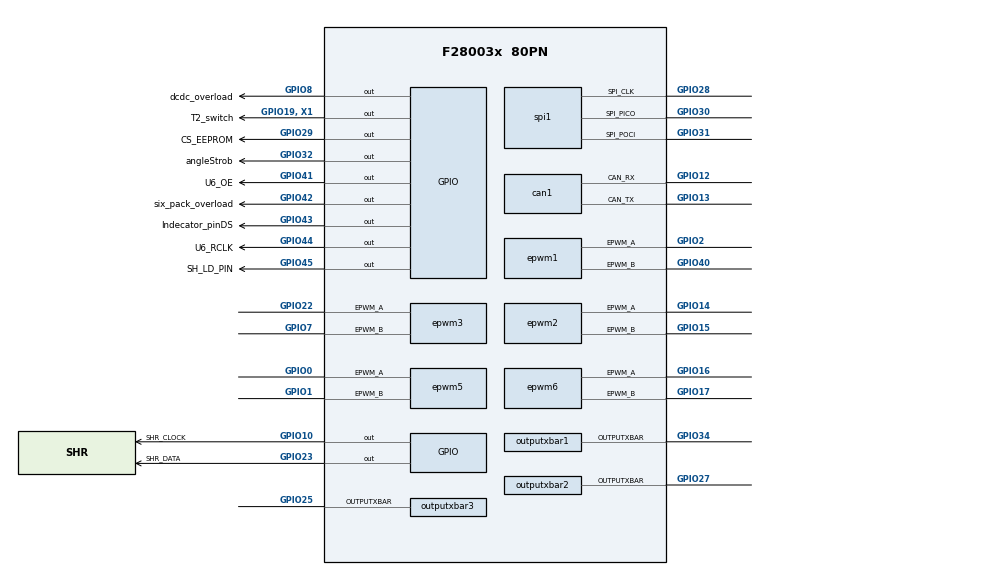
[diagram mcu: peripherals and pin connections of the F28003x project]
/**
 * @cliArgs --device "F28003x" --part "F28003x_80PN" --package "80PN" --context "system" --product "C2000WARE@6.00.01.00"
 * @versions {"tool":"1.27.0+4565"}
 */

/**
 * Import the modules used in this configuration.
 */
const adc              = scripting.addModule("/driverlib/adc.js", {}, false);
const adc1             = adc.addInstance();
const adc2             = adc.addInstance();
const adc3             = adc.addInstance();
const analog           = scripting.addModule("/driverlib/analog.js", {}, false);
const analog1          = analog.addInstance();
const asysctl          = scripting.addModule("/driverlib/asysctl.js");
const can              = scripting.addModule("/driverlib/can.js", {}, false);
const can1             = can.addInstance();
const cla              = scripting.addModule("/driverlib/cla.js", {}, false);
const cla1             = cla.addInstance();
const cmpss            = scripting.addModule("/driverlib/cmpss.js", {}, false);
const cmpss1           = cmpss.addInstance();
const cmpss2           = cmpss.addInstance();
const cmpss3           = cmpss.addInstance();
const cputimer         = scripting.addModule("/driverlib/cputimer.js", {}, false);
const cputimer1        = cputimer.addInstance();
const cputimer2        = cputimer.addInstance();
const device_support   = scripting.addModule("/driverlib/device_support.js");
const dma              = scripting.addModule("/driverlib/dma.js", {}, false);
const dma1             = dma.addInstance();
const epwm             = scripting.addModule("/driverlib/epwm.js");
const epwm1            = epwm.addInstance();
const epwm2            = epwm.addInstance();
const epwm3            = epwm.addInstance();
const epwm4            = epwm.addInstance();
const epwm5            = epwm.addInstance();
const epwm6            = epwm.addInstance();
const epwmxbar         = scripting.addModule("/driverlib/epwmxbar.js", {}, false);
const epwmxbar1        = epwmxbar.addInstance();
const epwmxbar2        = epwmxbar.addInstance();
const gpio             = scripting.addModule("/driverlib/gpio.js", {}, false);
const gpio1            = gpio.addInstance();
const gpio2            = gpio.addInstance();
const gpio3            = gpio.addInstance();
const gpio4            = gpio.addInstance();
const gpio5            = gpio.addInstance();
const gpio6            = gpio.addInstance();
const gpio7            = gpio.addInstance();
const gpio8            = gpio.addInstance();
const gpio9            = gpio.addInstance();
const gpio10           = gpio.addInstance();
const gpio11           = gpio.addInstance();
const inputxbar_input  = scripting.addModule("/driverlib/inputxbar_input.js", {}, false);
const inputxbar_input1 = inputxbar_input.addInstance();
const inputxbar_input2 = inputxbar_input.addInstance();
const memcfg           = scripting.addModule("/driverlib/memcfg.js");
const outputxbar       = scripting.addModule("/driverlib/outputxbar.js", {}, false);
const outputxbar1      = outputxbar.addInstance();
const outputxbar2      = outputxbar.addInstance();
const outputxbar3      = outputxbar.addInstance();
const outputxbar4      = outputxbar.addInstance();
const spi              = scripting.addModule("/driverlib/spi.js", {}, false);
const spi1             = spi.addInstance();
const sync             = scripting.addModule("/driverlib/sync.js");
const sysctl           = scripting.addModule("/driverlib/sysctl.js");

/**
 * Write custom configuration values to the imported modules.
 */
adc1.soc0UseSampleTimeCalculator    = true;
adc1.interruptPulseMode             = "ADC_PULSE_END_OF_CONV";
adc1.$name                          = "myADCA";
adc1.adcClockPrescaler              = "ADC_CLK_DIV_2_0";
adc1.ppb2SOCNumber                  = "ADC_SOC_NUMBER1";
adc1.ppb2HighTripLimit              = 4000;
adc1.ppb1HighTripLimit              = 2000;
adc1.ppb1LowTripLimit               = -2000;
adc1.enableInterrupt1               = true;
adc1.soc1SampleWindow               = 12;
adc1.soc0SampleWindow               = 12;
adc1.ppb2ReferenceOffset            = 2048;
adc1.socHighPriorityMode            = "ADC_PRI_ALL_HIPRI";
adc1.soc0Trigger                    = "ADC_TRIGGER_EPWM1_SOCA";
adc1.soc1Trigger                    = "ADC_TRIGGER_EPWM1_SOCA";
adc1.soc2Trigger                    = "ADC_TRIGGER_EPWM1_SOCA";
adc1.interrupt1SOCSource            = "ADC_SOC_NUMBER2";
adc1.enabledPPBs                    = ["ADC_PPB_NUMBER1","ADC_PPB_NUMBER2","ADC_PPB_NUMBER3"];
adc1.ppb3SOCNumber                  = "ADC_SOC_NUMBER2";
adc1.ppb3ReferenceOffset            = 2048;
adc1.soc2SampleWindow               = 12;
adc1.soc0Name                       = "SOC0_Udc";
adc1.soc0Channel                    = "ADC_CH_ADCIN15";
adc1.soc1Name                       = "SOC1_Vin";
adc1.soc1Channel                    = "ADC_CH_ADCIN4";
adc1.soc2Name                       = "SOC2_Idc";
adc1.soc2Channel                    = "ADC_CH_ADCIN12";
adc1.ppb1ReferenceOffset            = 200;
adc1.enableInterrupt1ContinuousMode = true;
adc1.soc3Channel                    = "ADC_CH_ADCIN10";
adc1.soc3Trigger                    = "ADC_TRIGGER_EPWM2_SOCA";
adc1.soc3SampleWindow               = 12;
adc1.interrupt2SOCSource            = "ADC_SOC_NUMBER3";
adc1.registerInterrupts             = ["1"];
adc1.enabledSOCs                    = ["ADC_SOC_NUMBER0","ADC_SOC_NUMBER1","ADC_SOC_NUMBER2"];
adc1.enabledInts                    = ["ADC_INT_NUMBER1"];
adc1.adcInt1.interruptHandler       = "Cla1Task1";

adc2.$name                          = "myADCB";
adc2.adcBase                        = "ADCB_BASE";
adc2.adcClockPrescaler              = "ADC_CLK_DIV_2_0";
adc2.interruptPulseMode             = "ADC_PULSE_END_OF_CONV";
adc2.enableInterrupt2               = true;
adc2.soc0Trigger                    = "ADC_TRIGGER_EPWM2_SOCA";
adc2.socHighPriorityMode            = "ADC_PRI_ALL_HIPRI";
adc2.enabledInts                    = ["ADC_INT_NUMBER1"];
adc2.ppb2SOCNumber                  = "ADC_SOC_NUMBER1";
adc2.soc2Channel                    = "ADC_CH_ADCIN9";
adc2.enableInterrupt1               = true;
adc2.ppb3SOCNumber                  = "ADC_SOC_NUMBER2";
adc2.ppb2ReferenceOffset            = 2048;
adc2.ppb1ReferenceOffset            = 2048;
adc2.soc1Trigger                    = "ADC_TRIGGER_EPWM2_SOCA";
adc2.soc2Trigger                    = "ADC_TRIGGER_EPWM2_SOCA";
adc2.soc2Name                       = "SOC2_Udc";
adc2.soc2SampleWindow               = 120;
adc2.soc0Name                       = "SOC0_Ia";
adc2.soc1Name                       = "SOC1_Ib";
adc2.enabledSOCs                    = ["ADC_SOC_NUMBER0","ADC_SOC_NUMBER1"];
adc2.interrupt1SOCSource            = "ADC_SOC_NUMBER1";
adc2.enabledPPBs                    = ["ADC_PPB_NUMBER1","ADC_PPB_NUMBER2"];
adc2.enableInterrupt1ContinuousMode = true;
adc2.soc0SampleWindow               = 120;
adc2.soc0Channel                    = "ADC_CH_ADCIN1";
adc2.soc1Channel                    = "ADC_CH_ADCIN7";
adc2.soc1SampleWindow               = 12;

adc3.$name                          = "myADCC";
adc3.adcBase                        = "ADCC_BASE";
adc3.adcClockPrescaler              = "ADC_CLK_DIV_2_0";
adc3.enabledSOCs                    = ["ADC_SOC_NUMBER0"];
adc3.soc0Channel                    = "ADC_CH_ADCIN12";
adc3.soc0Trigger                    = "ADC_TRIGGER_EPWM2_SOCA";
adc3.soc0SampleWindow               = 512;
adc3.interruptPulseMode             = "ADC_PULSE_END_OF_CONV";
adc3.enabledInts                    = ["ADC_INT_NUMBER1"];
adc3.enableInterrupt1               = true;
adc3.enableInterrupt1ContinuousMode = true;
adc3.registerInterrupts             = ["1"];
adc3.adcInt1.enableInterrupt        = true;

asysctl.enableTemperatureSensor = true;
asysctl.analogReference         = "INTERNAL";
asysctl.analogReferenceVoltage  = "1P65";

can1.AutoBusOnTimer        = 10;
can1.bitRate               = "1000000";
can1.msgObjsUsed           = [1,2,3,4,5,6,7,8,9,10,11,12,13,32];
can1.$name                 = "myDCAN";
can1.can.$assign           = "CANA";
can1.can.can_rxPin.$assign = "GPIO12";
can1.can.can_txPin.$assign = "GPIO13";
can1.rxQual.padConfig      = "STD";
can1.txQual.padConfig      = "STD";
can1.msgObj1.$name         = "msgObj2";
can1.msgObj1.msgLen        = 8;
can1.msgObj1.msgID         = 2;
can1.msgObj2.$name         = "msgObj3";
can1.msgObj2.msgType       = "CAN_MSG_OBJ_TYPE_TX";
can1.msgObj2.msgLen        = 8;
can1.msgObj2.msgID         = 1;
can1.msgObj3.$name         = "msgObj4";
can1.msgObj3.msgType       = "CAN_MSG_OBJ_TYPE_TX";
can1.msgObj3.msgLen        = 8;
can1.msgObj3.msgID         = 103;
can1.msgObj4.$name         = "msgObj0";
can1.msgObj4.msgType       = "CAN_MSG_OBJ_TYPE_TX";
can1.msgObj4.msgLen        = 8;
can1.msgObj4.msgID         = 104;
can1.msgObj5.$name         = "msgObj5";
can1.msgObj5.msgType       = "CAN_MSG_OBJ_TYPE_TX";
can1.msgObj5.msgLen        = 8;
can1.msgObj5.msgID         = 110;
can1.msgObj6.$name         = "msgObj6";
can1.msgObj6.msgID         = 100;
can1.msgObj6.msgType       = "CAN_MSG_OBJ_TYPE_TX";
can1.msgObj6.msgLen        = 8;
can1.msgObj7.$name         = "msgObj7";
can1.msgObj7.msgID         = 101;
can1.msgObj7.msgType       = "CAN_MSG_OBJ_TYPE_TX";
can1.msgObj7.msgLen        = 8;
can1.msgObj8.$name         = "msgObj8";
can1.msgObj8.msgID         = 102;
can1.msgObj8.msgType       = "CAN_MSG_OBJ_TYPE_TX";
can1.msgObj8.msgLen        = 8;
can1.msgObj9.$name         = "msgObj9";
can1.msgObj9.msgID         = 107;
can1.msgObj9.msgType       = "CAN_MSG_OBJ_TYPE_TX";
can1.msgObj9.msgLen        = 8;
can1.msgObj10.$name        = "msgObj10";
can1.msgObj10.msgID        = 106;
can1.msgObj10.msgType      = "CAN_MSG_OBJ_TYPE_TX";
can1.msgObj10.msgLen       = 8;
can1.msgObj11.$name        = "msgObj11";
can1.msgObj11.msgID        = 109;
can1.msgObj11.msgType      = "CAN_MSG_OBJ_TYPE_TX";
can1.msgObj11.msgLen       = 8;
can1.msgObj12.$name        = "msgObj12";
can1.msgObj12.msgType      = "CAN_MSG_OBJ_TYPE_TX";
can1.msgObj12.msgLen       = 8;
can1.msgObj12.msgID        = 118;
can1.msgObj13.$name        = "msgObj13";
can1.msgObj13.msgID        = 116;
can1.msgObj13.msgType      = "CAN_MSG_OBJ_TYPE_TX";
can1.msgObj13.msgLen       = 8;
can1.msgObj32.$name        = "msgObj1";
can1.msgObj32.msgType      = "CAN_MSG_OBJ_TYPE_TX";
can1.msgObj32.msgLen       = 8;
can1.msgObj32.msgID        = 131;

cla1.enable_CLA_TASK_2  = false;
cla1.enable_CLA_TASK_3  = false;
cla1.enable_CLA_TASK_4  = false;
cla1.enable_CLA_TASK_5  = false;
cla1.enable_CLA_TASK_6  = false;
cla1.enable_CLA_TASK_8  = false;
cla1.cpuint_CLA_TASK_2  = false;
cla1.cpuint_CLA_TASK_3  = false;
cla1.cpuint_CLA_TASK_4  = false;
cla1.cpuint_CLA_TASK_5  = false;
cla1.cpuint_CLA_TASK_6  = false;
cla1.cpuint_CLA_TASK_8  = false;
cla1.$name              = "myCLA";
cla1.cpuint_CLA_TASK_1  = false;
cla1.trigger_CLA_TASK_1 = "CLA_TRIGGER_ADCA1";
cla1.trigger_CLA_TASK_7 = "CLA_TRIGGER_ADCB1";

const divider2       = system.clockTree["LOSPCP"];
divider2.divideValue = 1;

const divider3       = system.clockTree["MCANACLKDIV"];
divider3.divideValue = 3;

cmpss1.initFilterHigh      = true;
cmpss1.initFilterLow       = true;
cmpss1.dacValHigh          = 3700;
cmpss1.dacValLow           = 400;
cmpss1.dacValLoad          = "CMPSS_DACVAL_PWMSYNC";
cmpss1.$name               = "IphV";
cmpss1.highCTRIPOUT        = "CMPSS_TRIPOUT_FILTER";
cmpss1.highCTRIP           = "CMPSS_TRIP_FILTER";
cmpss1.samplePrescaleHigh  = 8;
cmpss1.sampleWindowHigh    = 32;
cmpss1.thresholdHigh       = 32;
cmpss1.samplePrescaleLow   = 8;
cmpss1.sampleWindowLow     = 32;
cmpss1.thresholdLow        = 32;
cmpss1.lowCTRIPOUT         = "CMPSS_TRIPOUT_FILTER";
cmpss1.lowCTRIP            = "CMPSS_TRIP_FILTER";
cmpss1.configBlanking      = "2";
cmpss1.pwmSyncSrc          = "2";
cmpss1.asysCMPHPMXSELValue = "4";
cmpss1.asysCMPLPMXSELValue = "4";
cmpss1.lowCompInvert       = true;
cmpss1.enableModule        = true;

cmpss2.enableModule        = true;
cmpss2.dacValLoad          = "CMPSS_DACVAL_PWMSYNC";
cmpss2.hysteresisVal       = "4";
cmpss2.lowCompInvert       = true;
cmpss2.initFilterHigh      = true;
cmpss2.initFilterLow       = true;
cmpss2.lowCTRIPOUT         = "CMPSS_TRIPOUT_FILTER";
cmpss2.highCTRIPOUT        = "CMPSS_TRIPOUT_FILTER";
cmpss2.sampleWindowLow     = 31;
cmpss2.sampleWindowHigh    = 31;
cmpss2.configBlanking      = "2";
cmpss2.highCTRIP           = "CMPSS_TRIP_FILTER";
cmpss2.lowCTRIP            = "CMPSS_TRIP_FILTER";
cmpss2.dacValHigh          = 3700;
cmpss2.thresholdHigh       = 30;
cmpss2.dacValLow           = 400;
cmpss2.clearFilterLatchLow = true;
cmpss2.latchResetLow       = true;
cmpss2.thresholdLow        = 30;
cmpss2.configLatchLow      = true;
cmpss2.samplePrescaleHigh  = 16;
cmpss2.samplePrescaleLow   = 16;
cmpss2.cmpssBase           = "CMPSS2_BASE";
cmpss2.$name               = "Idc";

cmpss3.initFilterLow       = true;
cmpss3.sampleWindowLow     = 31;
cmpss3.highCTRIP           = "CMPSS_TRIP_FILTER";
cmpss3.lowCTRIP            = "CMPSS_TRIP_FILTER";
cmpss3.cmpssBase           = "CMPSS3_BASE";
cmpss3.asysCMPLPMXSELValue = "2";
cmpss3.lowCTRIPOUT         = "CMPSS_TRIPOUT_FILTER";
cmpss3.thresholdLow        = 31;
cmpss3.highCTRIPOUT        = "CMPSS_TRIPOUT_FILTER";
cmpss3.initFilterHigh      = true;
cmpss3.sampleWindowHigh    = 32;
cmpss3.thresholdHigh       = 32;
cmpss3.samplePrescaleHigh  = 8;
cmpss3.$name               = "IphU";
cmpss3.configBlanking      = "2";
cmpss3.lowCompInvert       = true;
cmpss3.samplePrescaleLow   = 8;
cmpss3.dacValHigh          = 4000;
cmpss3.dacValLow           = 1000;
cmpss3.pwmSyncSrc          = "2";
cmpss3.asysCMPHPMXSELValue = "2";
cmpss3.enableModule        = true;

analog1.$name            = "myANALOGPinMux0";
adc1.analog              = analog1;
adc2.analog              = analog1;
cmpss1.analog            = analog1;
cmpss2.analog            = analog1;
cmpss3.analog            = analog1;
analog1.useCase          = "CUSTOM";
analog1.useInterfacePins = ["A0/B15/C15/DACA_OUT","A1/B7/DACB_OUT","A10/B1/C10","A11/B10/C0","A12, C1","A15, C7/B9","A4/B8, C14"];
adc3.analog              = analog1;

cputimer1.$name          = "myCPUTIMER0";
cputimer1.timerPeriod    = 2400000;
cputimer1.emulationMode  = "CPUTIMER_EMULATIONMODE_RUNFREE";
cputimer1.timerPrescaler = 1;

cputimer2.$name          = "myCPUTIMER1";
cputimer2.cputimerBase   = "CPUTIMER1_BASE";
cputimer2.emulationMode  = "CPUTIMER_EMULATIONMODE_RUNFREE";
cputimer2.timerPeriod    = 2400000;
cputimer2.timerPrescaler = 1;

dma1.enableTriggers         = true;
dma1.triggerSource          = "DMA_TRIGGER_CANAIF3";
dma1.useInterrupts          = true;
dma1.registerInterrupts     = true;
dma1.enableInterrupts       = true;
dma1.interruptMode          = "DMA_INT_AT_END";
dma1.continuousModeConfig   = "DMA_CFG_CONTINUOUS_ENABLE";
dma1.startChannel           = true;
dma1.srcBurstStep           = 1;
dma1.destBurstStep          = 1;
dma1.destWrapSize           = 100;
dma1.emulationMode          = "DMA_EMULATION_FREE_RUN";
dma1.databusWidthConfig     = "DMA_CFG_SIZE_32BIT";
dma1.burstSize              = 2;
dma1.oneShotConfig          = "DMA_CFG_ONESHOT_ENABLE";
dma1.dmaBase                = "DMA_CH6_BASE";
dma1.$name                  = "DMA6";
dma1.dmaInt.enableInterrupt = true;

epwm.commentOutDefaultCode = true;
epwm.generateInitFunctions = true;

epwm1.epwmTimebase_emulationMode                                          = "EPWM_EMULATION_FREE_RUN";
epwm1.epwmTimebase_hsClockDiv                                             = "EPWM_HSCLOCK_DIVIDER_1";
epwm1.epwmTimebase_counterMode                                            = "EPWM_COUNTER_MODE_UP_DOWN";
epwm1.epwmCounterCompare_cmpB                                             = 1;
epwm1.epwmCounterCompare_enableShadowLoadModeCMPB                         = false;
epwm1.epwmActionQualifier_EPWM_AQ_OUTPUT_A_shadowMode                     = true;
epwm1.epwmDeadband_enableRED                                              = true;
epwm1.epwmDeadband_enableFED                                              = true;
epwm1.epwmDeadband_dbControlGld                                           = true;
epwm1.epwmDeadband_redGld                                                 = true;
epwm1.epwmDeadband_fedGld                                                 = true;
epwm1.epwmTimebase_counterModeAfterSync                                   = "EPWM_COUNT_MODE_UP_AFTER_SYNC";
epwm1.epwmActionQualifier_EPWM_AQ_OUTPUT_B_shadowMode                     = true;
epwm1.epwmDigitalCompare_EPWM_TZ_DC_OUTPUT_A1                             = "EPWM_TZ_EVENT_DCXH_HIGH";
epwm1.epwmTimebase_periodGld                                              = true;
epwm1.epwmDigitalCompare_EPWM_DC_TYPE_DCAH                                = "EPWM_DC_TRIP_TRIPIN4";
epwm1.epwmTimebase_period                                                 = 60000;
epwm1.copyFrom                                                            = "myEPWM4";
epwm1.epwmTimebase_syncInPulseSource                                      = "EPWM_SYNC_IN_PULSE_SRC_DISABLE";
epwm1.epwmTimebase_syncOutPulseMode                                       = ["EPWM_SYNC_OUT_PULSE_ON_CNTR_ZERO"];
epwm1.epwmActionQualifier_t1Source                                        = "EPWM_AQ_TRIGGER_EVENT_TRIG_TZ_1";
epwm1.epwmActionQualifier_t2Source                                        = "EPWM_AQ_TRIGGER_EVENT_TRIG_TZ_1";
epwm1.epwmTripZone_registerInterrupts                                     = true;
epwm1.epwmDigitalCompare_EPWM_DC_MODULE_A_EPWM_DC_EVENT_1_latchClearEvent = "EPWM_DC_CBC_LATCH_CLR_ON_CNTR_PERIOD";
epwm1.epwmDigitalCompare_EPWM_DC_MODULE_A_EPWM_DC_EVENT_2_eventSync       = "EPWM_DC_EVENT_INPUT_NOT_SYNCED";
epwm1.epwmEventTrigger_EPWM_SOC_A_triggerEnable                           = true;
epwm1.epwmEventTrigger_EPWM_SOC_A_triggerEventPrescalar                   = "1";
epwm1.epwmDigitalCompare_EPWM_DC_TYPE_DCBH                                = "EPWM_DC_TRIP_TRIPIN4";
epwm1.epwmDigitalCompare_EPWM_TZ_DC_OUTPUT_B1                             = "EPWM_TZ_EVENT_DCXH_HIGH";
epwm1.epwmTripZone_tzInterruptSource                                      = ["EPWM_TZ_INTERRUPT_OST"];
epwm1.epwmTripZone_oneShotSource                                          = ["EPWM_TZ_SIGNAL_DCAEVT1","EPWM_TZ_SIGNAL_DCBEVT1"];
epwm1.epwmTripZone_EPWM_TZ_ACTION_EVENT_DCAEVT1                           = "EPWM_TZ_ACTION_DISABLE";
epwm1.epwmTripZone_EPWM_TZ_ACTION_EVENT_DCAEVT2                           = "EPWM_TZ_ACTION_DISABLE";
epwm1.epwmTripZone_EPWM_TZ_ACTION_EVENT_DCBEVT1                           = "EPWM_TZ_ACTION_DISABLE";
epwm1.epwmTripZone_EPWM_TZ_ACTION_EVENT_DCBEVT2                           = "EPWM_TZ_ACTION_DISABLE";
epwm1.$name                                                               = "EPWM2_Iu";
epwm1.epwmActionQualifier_EPWM_AQ_OUTPUT_A_ON_TIMEBASE_UP_CMPA            = "EPWM_AQ_OUTPUT_LOW";
epwm1.epwmActionQualifier_EPWM_AQ_OUTPUT_A_ON_TIMEBASE_DOWN_CMPA          = "EPWM_AQ_OUTPUT_HIGH";
epwm1.epwmDeadband_polarityRED                                            = "EPWM_DB_POLARITY_ACTIVE_LOW";
epwm1.epwmDeadband_delayRED                                               = 120;
epwm1.epwmDeadband_delayFED                                               = 120;
epwm1.epwmTripZone_EPWM_TZ_ACTION_EVENT_TZA                               = "EPWM_TZ_ACTION_HIGH";
epwm1.epwmTripZone_EPWM_TZ_ACTION_EVENT_TZB                               = "EPWM_TZ_ACTION_HIGH";
epwm1.epwmCounterCompare_cmpA                                             = 1;
epwm1.epwmEventTrigger_EPWM_SOC_A_triggerSource                           = "EPWM_SOC_TBCTR_ZERO";
epwm1.epwm.$assign                                                        = "EPWM2";
epwm1.epwm.epwm_aPin.$assign                                              = "GPIO2";
epwm1.epwm.epwm_bPin.$assign                                              = "GPIO40";
epwm1.epwmTZInt.enableInterrupt                                           = true;

epwm2.epwmTimebase_emulationMode                                 = "EPWM_EMULATION_FREE_RUN";
epwm2.epwmTimebase_hsClockDiv                                    = "EPWM_HSCLOCK_DIVIDER_1";
epwm2.epwmTimebase_counterMode                                   = "EPWM_COUNTER_MODE_UP_DOWN";
epwm2.epwmCounterCompare_cmpB                                    = 1;
epwm2.epwmCounterCompare_enableShadowLoadModeCMPB                = false;
epwm2.epwmActionQualifier_EPWM_AQ_OUTPUT_A_shadowMode            = true;
epwm2.epwmDeadband_enableRED                                     = true;
epwm2.epwmDeadband_enableFED                                     = true;
epwm2.epwmDeadband_dbControlGld                                  = true;
epwm2.epwmDeadband_redGld                                        = true;
epwm2.epwmDeadband_fedGld                                        = true;
epwm2.epwmTimebase_phaseEnable                                   = true;
epwm2.epwmTimebase_counterModeAfterSync                          = "EPWM_COUNT_MODE_UP_AFTER_SYNC";
epwm2.epwmActionQualifier_EPWM_AQ_OUTPUT_B_shadowMode            = true;
epwm2.epwmTimebase_periodLoadEvent                               = "EPWM_SHADOW_LOAD_MODE_SYNC";
epwm2.epwmDigitalCompare_EPWM_TZ_DC_OUTPUT_A1                    = "EPWM_TZ_EVENT_DCXH_HIGH";
epwm2.epwmEventTrigger_EPWM_SOC_A_triggerEnable                  = true;
epwm2.epwmEventTrigger_EPWM_SOC_A_triggerSource                  = "EPWM_SOC_TBCTR_PERIOD";
epwm2.epwmEventTrigger_EPWM_SOC_A_triggerEventPrescalar          = "1";
epwm2.epwmTimebase_periodGld                                     = true;
epwm2.epwmTripZone_EPWM_TZ_ACTION_EVENT_DCAEVT1                  = "EPWM_TZ_ACTION_DISABLE";
epwm2.epwmTripZone_EPWM_TZ_ACTION_EVENT_DCAEVT2                  = "EPWM_TZ_ACTION_DISABLE";
epwm2.epwmTripZone_EPWM_TZ_ACTION_EVENT_DCBEVT1                  = "EPWM_TZ_ACTION_DISABLE";
epwm2.epwmTripZone_EPWM_TZ_ACTION_EVENT_DCBEVT2                  = "EPWM_TZ_ACTION_DISABLE";
epwm2.epwmDigitalCompare_EPWM_DC_TYPE_DCAH                       = "EPWM_DC_TRIP_TRIPIN4";
epwm2.epwmTimebase_period                                        = 60000;
epwm2.epwmCounterCompare_cmpA                                    = 30000;
epwm2.copyFrom                                                   = "myEPWM4";
epwm2.epwmTimebase_periodLink                                    = "EPWM_LINK_WITH_EPWM_2";
epwm2.epwmTimebase_syncInPulseSource                             = "EPWM_SYNC_IN_PULSE_SRC_SYNCOUT_EPWM2";
epwm2.$name                                                      = "EPWM3_Iw";
epwm2.epwmTripZone_oneShotSource                                 = ["EPWM_TZ_SIGNAL_DCAEVT1","EPWM_TZ_SIGNAL_DCBEVT1"];
epwm2.epwmActionQualifier_EPWM_AQ_OUTPUT_A_ON_TIMEBASE_UP_CMPA   = "EPWM_AQ_OUTPUT_LOW";
epwm2.epwmActionQualifier_EPWM_AQ_OUTPUT_A_ON_TIMEBASE_DOWN_CMPA = "EPWM_AQ_OUTPUT_HIGH";
epwm2.epwmDeadband_polarityRED                                   = "EPWM_DB_POLARITY_ACTIVE_LOW";
epwm2.epwmDeadband_delayRED                                      = 120;
epwm2.epwmDeadband_delayFED                                      = 120;
epwm2.epwmTripZone_EPWM_TZ_ACTION_EVENT_TZA                      = "EPWM_TZ_ACTION_HIGH";
epwm2.epwmTripZone_EPWM_TZ_ACTION_EVENT_TZB                      = "EPWM_TZ_ACTION_HIGH";
epwm2.epwm.$assign                                               = "EPWM3";
epwm2.epwm.epwm_aPin.$assign                                     = "GPIO14";
epwm2.epwm.epwm_bPin.$assign                                     = "GPIO15";

epwm3.copyFrom                                                            = "myEPWM1";
epwm3.epwmTimebase_emulationMode                                          = "EPWM_EMULATION_FREE_RUN";
epwm3.epwmTimebase_hsClockDiv                                             = "EPWM_HSCLOCK_DIVIDER_1";
epwm3.epwmTimebase_period                                                 = 60000;
epwm3.epwmTimebase_periodGld                                              = true;
epwm3.epwmTimebase_counterMode                                            = "EPWM_COUNTER_MODE_UP_DOWN";
epwm3.epwmTimebase_counterModeAfterSync                                   = "EPWM_COUNT_MODE_UP_AFTER_SYNC";
epwm3.epwmTimebase_syncOutPulseMode                                       = ["EPWM_SYNC_OUT_PULSE_ON_CNTR_ZERO"];
epwm3.epwmCounterCompare_cmpA                                             = 30000;
epwm3.epwmCounterCompare_cmpB                                             = 1;
epwm3.epwmCounterCompare_enableShadowLoadModeCMPB                         = false;
epwm3.epwmActionQualifier_t1Source                                        = "EPWM_AQ_TRIGGER_EVENT_TRIG_TZ_1";
epwm3.epwmActionQualifier_t2Source                                        = "EPWM_AQ_TRIGGER_EVENT_TRIG_TZ_1";
epwm3.epwmActionQualifier_EPWM_AQ_OUTPUT_A_shadowMode                     = true;
epwm3.epwmActionQualifier_EPWM_AQ_OUTPUT_B_shadowMode                     = true;
epwm3.epwmDeadband_enableRED                                              = true;
epwm3.epwmDeadband_enableFED                                              = true;
epwm3.epwmDeadband_dbControlGld                                           = true;
epwm3.epwmDeadband_redGld                                                 = true;
epwm3.epwmDeadband_fedGld                                                 = true;
epwm3.epwmTripZone_EPWM_TZ_ACTION_EVENT_TZA                               = "EPWM_TZ_ACTION_DISABLE";
epwm3.epwmTripZone_EPWM_TZ_ACTION_EVENT_TZB                               = "EPWM_TZ_ACTION_DISABLE";
epwm3.epwmTripZone_EPWM_TZ_ACTION_EVENT_DCAEVT1                           = "EPWM_TZ_ACTION_DISABLE";
epwm3.epwmTripZone_EPWM_TZ_ACTION_EVENT_DCAEVT2                           = "EPWM_TZ_ACTION_DISABLE";
epwm3.epwmTripZone_EPWM_TZ_ACTION_EVENT_DCBEVT1                           = "EPWM_TZ_ACTION_DISABLE";
epwm3.epwmTripZone_EPWM_TZ_ACTION_EVENT_DCBEVT2                           = "EPWM_TZ_ACTION_DISABLE";
epwm3.epwmTripZone_oneShotSource                                          = ["EPWM_TZ_SIGNAL_DCAEVT1"];
epwm3.epwmTripZone_tzInterruptSource                                      = ["EPWM_TZ_INTERRUPT_OST"];
epwm3.epwmDigitalCompare_EPWM_DC_TYPE_DCAH                                = "EPWM_DC_TRIP_TRIPIN4";
epwm3.epwmDigitalCompare_EPWM_TZ_DC_OUTPUT_A1                             = "EPWM_TZ_EVENT_DCXH_HIGH";
epwm3.epwmDigitalCompare_EPWM_DC_MODULE_A_EPWM_DC_EVENT_1_latchClearEvent = "EPWM_DC_CBC_LATCH_CLR_ON_CNTR_PERIOD";
epwm3.epwmDigitalCompare_EPWM_DC_MODULE_A_EPWM_DC_EVENT_2_eventSync       = "EPWM_DC_EVENT_INPUT_NOT_SYNCED";
epwm3.epwmEventTrigger_EPWM_SOC_A_triggerEnable                           = true;
epwm3.epwmEventTrigger_EPWM_SOC_A_triggerSource                           = "EPWM_SOC_TBCTR_PERIOD";
epwm3.epwmEventTrigger_EPWM_SOC_A_triggerEventPrescalar                   = "1";
epwm3.epwmTimebase_periodLink                                             = "EPWM_LINK_WITH_EPWM_2";
epwm3.epwmTimebase_phaseEnable                                            = true;
epwm3.epwmTimebase_syncInPulseSource                                      = "EPWM_SYNC_IN_PULSE_SRC_SYNCOUT_EPWM2";
epwm3.$name                                                               = "EPWM4_Iv";
epwm3.epwmActionQualifier_EPWM_AQ_OUTPUT_A_ON_TIMEBASE_UP_CMPA            = "EPWM_AQ_OUTPUT_LOW";
epwm3.epwmActionQualifier_EPWM_AQ_OUTPUT_A_ON_TIMEBASE_DOWN_CMPA          = "EPWM_AQ_OUTPUT_HIGH";
epwm3.epwmDeadband_polarityRED                                            = "EPWM_DB_POLARITY_ACTIVE_LOW";
epwm3.epwmDeadband_delayRED                                               = 120;
epwm3.epwmDeadband_delayFED                                               = 120;
epwm3.epwm.$assign                                                        = "EPWM4";
epwm3.epwm.epwm_aPin.$assign                                              = "GPIO22";
epwm3.epwm.epwm_bPin.$assign                                              = "GPIO7";

epwm4.$name                      = "myEPWM7";
epwm4.useCase                    = "CUSTOM";
epwm4.epwmTimebase_hsClockDiv    = "EPWM_HSCLOCK_DIVIDER_1";
epwm4.epwmTimebase_period        = 65535;
epwm4.epwmTimebase_counterMode   = "EPWM_COUNTER_MODE_UP";
epwm4.epwmTimebase_emulationMode = "EPWM_EMULATION_FREE_RUN";
epwm4.epwm.$assign               = "EPWM7";

epwm5.epwmTimebase_emulationMode                                          = "EPWM_EMULATION_FREE_RUN";
epwm5.epwmTimebase_hsClockDiv                                             = "EPWM_HSCLOCK_DIVIDER_1";
epwm5.epwmTimebase_counterMode                                            = "EPWM_COUNTER_MODE_UP_DOWN";
epwm5.epwmActionQualifier_EPWM_AQ_OUTPUT_A_ON_TIMEBASE_UP_CMPA            = "EPWM_AQ_OUTPUT_HIGH";
epwm5.epwmActionQualifier_EPWM_AQ_OUTPUT_A_ON_TIMEBASE_DOWN_CMPA          = "EPWM_AQ_OUTPUT_LOW";
epwm5.epwmTimebase_counterModeAfterSync                                   = "EPWM_COUNT_MODE_UP_AFTER_SYNC";
epwm5.epwmDigitalCompare_EPWM_TZ_DC_OUTPUT_A1                             = "EPWM_TZ_EVENT_DCXH_HIGH";
epwm5.epwmEventTrigger_EPWM_SOC_A_triggerEnable                           = true;
epwm5.epwmEventTrigger_EPWM_SOC_A_triggerSource                           = "EPWM_SOC_TBCTR_PERIOD";
epwm5.epwmEventTrigger_EPWM_SOC_A_triggerEventPrescalar                   = "1";
epwm5.epwmTripZone_EPWM_TZ_ACTION_EVENT_DCAEVT1                           = "EPWM_TZ_ACTION_DISABLE";
epwm5.epwmTripZone_EPWM_TZ_ACTION_EVENT_DCAEVT2                           = "EPWM_TZ_ACTION_DISABLE";
epwm5.epwmTripZone_EPWM_TZ_ACTION_EVENT_DCBEVT1                           = "EPWM_TZ_ACTION_DISABLE";
epwm5.epwmTripZone_EPWM_TZ_ACTION_EVENT_DCBEVT2                           = "EPWM_TZ_ACTION_DISABLE";
epwm5.epwmTripZone_oneShotSource                                          = ["EPWM_TZ_SIGNAL_DCAEVT1"];
epwm5.epwmDigitalCompare_EPWM_DC_TYPE_DCAH                                = "EPWM_DC_TRIP_TRIPIN4";
epwm5.epwmTripZone_EPWM_TZ_ACTION_EVENT_TZA                               = "EPWM_TZ_ACTION_DISABLE";
epwm5.copyFrom                                                            = "myEPWM4";
epwm5.epwmTimebase_syncInPulseSource                                      = "EPWM_SYNC_IN_PULSE_SRC_DISABLE";
epwm5.epwmTimebase_syncOutPulseMode                                       = ["EPWM_SYNC_OUT_PULSE_ON_CNTR_ZERO"];
epwm5.epwmActionQualifier_t1Source                                        = "EPWM_AQ_TRIGGER_EVENT_TRIG_TZ_1";
epwm5.epwmActionQualifier_t2Source                                        = "EPWM_AQ_TRIGGER_EVENT_TRIG_TZ_1";
epwm5.epwmTripZone_EPWM_TZ_ACTION_EVENT_TZB                               = "EPWM_TZ_ACTION_DISABLE";
epwm5.epwmTripZone_tzInterruptSource                                      = ["EPWM_TZ_INTERRUPT_OST"];
epwm5.epwmDigitalCompare_EPWM_DC_MODULE_A_EPWM_DC_EVENT_1_latchClearEvent = "EPWM_DC_CBC_LATCH_CLR_ON_CNTR_PERIOD";
epwm5.epwmDigitalCompare_EPWM_DC_MODULE_A_EPWM_DC_EVENT_2_eventSync       = "EPWM_DC_EVENT_INPUT_NOT_SYNCED";
epwm5.$name                                                               = "myEPWM1";
epwm5.epwmDeadband_enableRED                                              = true;
epwm5.epwmDeadband_enableFED                                              = true;
epwm5.epwmCounterCompare_enableShadowLoadModeCMPB                         = false;
epwm5.epwmActionQualifier_EPWM_AQ_OUTPUT_A_shadowMode                     = true;
epwm5.hrpwm_syncSource                                                    = "HRPWM_PWMSYNC_SOURCE_ZERO";
epwm5.epwmTimebase_period                                                 = 1200;
epwm5.epwmCounterCompare_cmpA                                             = 600;
epwm5.epwmDeadband_delayRED                                               = 100;
epwm5.epwmDeadband_delayFED                                               = 100;
epwm5.epwmCounterCompare_cmpB                                             = 1;
epwm5.epwmDeadband_polarityFED                                            = "EPWM_DB_POLARITY_ACTIVE_LOW";
epwm5.epwm.$assign                                                        = "EPWM1";
epwm5.epwm.epwm_aPin.$assign                                              = "GPIO0";
epwm5.epwm.epwm_bPin.$assign                                              = "GPIO1";

epwm6.$name                                                      = "myEPWM5";
epwm6.epwmTimebase_hsClockDiv                                    = "EPWM_HSCLOCK_DIVIDER_1";
epwm6.epwmTimebase_periodLink                                    = "EPWM_LINK_WITH_EPWM_1";
epwm6.epwmTimebase_periodGld                                     = true;
epwm6.epwmTimebase_counterMode                                   = "EPWM_COUNTER_MODE_UP_DOWN";
epwm6.epwmTimebase_counterModeAfterSync                          = "EPWM_COUNT_MODE_UP_AFTER_SYNC";
epwm6.epwmTimebase_phaseEnable                                   = true;
epwm6.epwmActionQualifier_EPWM_AQ_OUTPUT_A_ON_TIMEBASE_UP_CMPA   = "EPWM_AQ_OUTPUT_HIGH";
epwm6.epwmActionQualifier_EPWM_AQ_OUTPUT_A_ON_TIMEBASE_DOWN_CMPA = "EPWM_AQ_OUTPUT_LOW";
epwm6.epwmDeadband_enableRED                                     = true;
epwm6.epwmDeadband_enableFED                                     = true;
epwm6.epwmDeadband_redGld                                        = true;
epwm6.epwmDeadband_fedGld                                        = true;
epwm6.useCase                                                    = "CUSTOM";
epwm6.useInterfacePins                                           = ["EPWM#_A","EPWM#_B"];
epwm6.epwmTimebase_phaseShift                                    = 1200;
epwm6.epwmCounterCompare_enableShadowLoadModeCMPB                = false;
epwm6.epwmTimebase_emulationMode                                 = "EPWM_EMULATION_FREE_RUN";
epwm6.epwmTimebase_periodLoadEvent                               = "EPWM_SHADOW_LOAD_MODE_SYNC";
epwm6.epwmCounterCompare_cmpALink                                = "EPWM_LINK_WITH_EPWM_1";
epwm6.epwmCounterCompare_cmpAGld                                 = true;
epwm6.epwmActionQualifier_EPWM_AQ_OUTPUT_A_gld                   = true;
epwm6.epwmActionQualifier_EPWM_AQ_OUTPUT_A_shadowMode            = true;
epwm6.epwmActionQualifier_EPWM_AQ_OUTPUT_A_shadowEvent           = "EPWM_AQ_LOAD_ON_SYNC_ONLY";
epwm6.epwmDeadband_delayRED                                      = 100;
epwm6.epwmDeadband_delayFED                                      = 100;
epwm6.epwmTimebase_period                                        = 1200;
epwm6.epwmCounterCompare_cmpA                                    = 600;
epwm6.epwmDeadband_polarityFED                                   = "EPWM_DB_POLARITY_ACTIVE_LOW";
epwm6.epwm.$assign                                               = "EPWM5";
epwm6.epwm.epwm_aPin.$assign                                     = "GPIO16";
epwm6.epwm.epwm_bPin.$assign                                     = "GPIO17";

epwmxbar1.$name         = "myEPWMXBAR0";
epwmxbar1.mux0Config    = "XBAR_EPWM_MUX00_CMPSS1_CTRIPH_OR_L";
epwmxbar1.mux4Config    = "XBAR_EPWM_MUX04_CMPSS3_CTRIPH_OR_L";
epwmxbar1.mux6Config    = "XBAR_EPWM_MUX06_CMPSS4_CTRIPH_OR_L";
epwmxbar1.mux7Config    = "XBAR_EPWM_MUX07_INPUTXBAR4";
epwmxbar1.sourceSignals = ["CMPSS1_CTRIPH_OR_L","CMPSS3_CTRIPH_OR_L"];

epwmxbar2.$name           = "Idc_null";
epwmxbar2.tripInput       = "XBAR_TRIP5";
epwmxbar2.useSourceSelect = true;
epwmxbar2.sourceSignals   = ["CMPSS2_CTRIPH"];

gpio1.padConfig       = "PULLUP";
gpio1.$name           = "CS_EEPROM";
gpio1.direction       = "GPIO_DIR_MODE_OUT";
gpio1.gpioPin.$assign = "GPIO29";

gpio2.$name           = "T2_switch";
gpio2.direction       = "GPIO_DIR_MODE_OUT";
gpio2.gpioPin.$assign = "GPIO19, X1";

gpio3.$name           = "angleStrob";
gpio3.direction       = "GPIO_DIR_MODE_OUT";
gpio3.gpioPin.$assign = "GPIO32";

gpio4.writeInitialValue = true;
gpio4.initialValue      = 1;
gpio4.$name             = "six_pack_overload";
gpio4.qualMode          = "GPIO_QUAL_ASYNC";
gpio4.gpioPin.$assign   = "GPIO42";

gpio5.$name             = "SH_LD_PIN";
gpio5.direction         = "GPIO_DIR_MODE_OUT";
gpio5.writeInitialValue = true;
gpio5.initialValue      = 1;
gpio5.gpioPin.$assign   = "GPIO45";

gpio6.direction         = "GPIO_DIR_MODE_OUT";
gpio6.writeInitialValue = true;
gpio6.$name             = "SHR_CLOCK";
gpio6.gpioPin.$assign   = "GPIO10";

gpio7.$name           = "SHR_DATA";
gpio7.gpioPin.$assign = "GPIO23";

gpio8.direction       = "GPIO_DIR_MODE_OUT";
gpio8.$name           = "Indecator_pinDS";
gpio8.gpioPin.$assign = "GPIO43";

gpio9.$name           = "U6_OE";
gpio9.direction       = "GPIO_DIR_MODE_OUT";
gpio9.padConfig       = "OD";
gpio9.gpioPin.$assign = "GPIO41";

gpio10.$name           = "U6_RCLK";
gpio10.direction       = "GPIO_DIR_MODE_OUT";
gpio10.gpioPin.$assign = "GPIO44";

gpio11.qualMode          = "GPIO_QUAL_ASYNC";
gpio11.$name             = "dcdc_overload";
gpio11.writeInitialValue = true;
gpio11.initialValue      = 1;
gpio11.gpioPin.$assign   = "GPIO8";

inputxbar_input1.inputxbarInput = "XBAR_INPUT4";
inputxbar_input1.inputxbarGpio  = "GPIO42";
inputxbar_input1.$name          = "inv_overload";

inputxbar_input2.$name         = "dc_convertor_overload";
inputxbar_input2.inputxbarGpio = "GPIO8";

memcfg.config_MEMCFG_SECT_LS0 = "CLA_prog";
memcfg.config_MEMCFG_SECT_LS2 = "CLA_data";
memcfg.config_MEMCFG_SECT_LS1 = "CLA_data";
memcfg.access_MEMCFG_SECT_GS0 = ["MEMCFG_PROT_ALLOWCPUFETCH","MEMCFG_PROT_ALLOWCPUWRITE","MEMCFG_PROT_ALLOWDMAWRITE"];
memcfg.access_MEMCFG_SECT_GS1 = ["MEMCFG_PROT_ALLOWCPUFETCH","MEMCFG_PROT_ALLOWCPUWRITE","MEMCFG_PROT_ALLOWDMAWRITE"];
memcfg.access_MEMCFG_SECT_GS2 = ["MEMCFG_PROT_ALLOWCPUFETCH","MEMCFG_PROT_ALLOWCPUWRITE"];
memcfg.access_MEMCFG_SECT_GS3 = ["MEMCFG_PROT_ALLOWCPUFETCH","MEMCFG_PROT_ALLOWCPUWRITE"];

outputxbar1.$name                            = "myOUTPUTXBAR0";
outputxbar1.useSourceSelect                  = true;
outputxbar1.sourceSignals                    = ["CMPSS1_CTRIPOUTH_OR_L","CMPSS3_CTRIPOUTH_OR_L"];
outputxbar1.outputxbar.$assign               = "OUTPUTXBAR1";
outputxbar1.outputxbar.outputxbarPin.$assign = "GPIO34";

outputxbar2.useSourceSelect                  = true;
outputxbar2.sourceSignals                    = ["CMPSS1_CTRIPOUTH_OR_L"];
outputxbar2.$name                            = "cmp1HL";
outputxbar2.outputxbar.$assign               = "OUTPUTXBAR4";
outputxbar2.outputxbar.outputxbarPin.$assign = "GPIO27";

outputxbar3.$name                            = "myOUTPUTXBAR2";
outputxbar3.useSourceSelect                  = true;
outputxbar3.sourceSignals                    = ["CMPSS4_CTRIPOUTH_OR_L"];
outputxbar3.outputxbar.$assign               = "OUTPUTXBAR2";
outputxbar3.outputxbar.outputxbarPin.$assign = "GPIO25";

outputxbar4.useSourceSelect                                = true;
outputxbar4.sourceSignals                                  = ["CMPSS1_CTRIPOUTH_OR_L","CMPSS3_CTRIPOUTH_OR_L"];
outputxbar4.$name                                          = "cmp13HL";
outputxbar4.outputxbar.$assign                             = "OUTPUTXBAR3";
outputxbar4.outputxbar.outputxbarPin.$assignAllowConflicts = "GPIO26";

spi1.mode                    = "SPI_MODE_CONTROLLER";
spi1.$name                   = "mySPIB";
spi1.enabledInterrupts       = ["SPI_INT_RX_DATA_TX_EMPTY"];
spi1.txFifo                  = "SPI_FIFO_TX2";
spi1.rxFifo                  = "SPI_FIFO_RX2";
spi1.useInterfacePins        = ["SPI@_CLK","SPI@_SIMO","SPI@_SOMI"];
spi1.useInterrupts           = false;
spi1.useCase                 = "CUSTOM";
spi1.emulationMode           = "SPI_EMULATION_FREE_RUN";
spi1.bitRate                 = 30000000;
spi1.picoQual.$name          = "myGPIOQUAL0";
spi1.pociQual.$name          = "myGPIOQUAL3";
spi1.clkQual.$name           = "myGPIOQUAL2";
spi1.spi.$assign             = "SPIB";
spi1.spi.spi_picoPin.$assign = "GPIO30";
spi1.spi.spi_pociPin.$assign = "GPIO31";
spi1.spi.spi_clkPin.$assign  = "GPIO28";

sync.syncOutSource       = "SYSCTL_SYNC_OUT_SRC_EPWM2SYNCOUT";
sync.ADCSOCAOutputSelect = ["SYSCTL_ADCSOC_SRC_PWM2SOCA"];

sysctl.enable_SYSCTL_PERIPH_CLK_CPUBGCRC = false;
sysctl.enable_SYSCTL_PERIPH_CLK_HRCAL    = false;
sysctl.enable_SYSCTL_PERIPH_CLK_ERAD     = false;
sysctl.enable_SYSCTL_PERIPH_CLK_ECAP1    = false;
sysctl.enable_SYSCTL_PERIPH_CLK_ECAP2    = false;
sysctl.enable_SYSCTL_PERIPH_CLK_ECAP3    = false;
sysctl.enable_SYSCTL_PERIPH_CLK_EQEP1    = false;
sysctl.enable_SYSCTL_PERIPH_CLK_EQEP2    = false;
sysctl.enable_SYSCTL_PERIPH_CLK_SD1      = false;
sysctl.enable_SYSCTL_PERIPH_CLK_SD2      = false;
sysctl.enable_SYSCTL_PERIPH_CLK_SCIA     = false;
sysctl.enable_SYSCTL_PERIPH_CLK_SCIB     = false;
sysctl.enable_SYSCTL_PERIPH_CLK_SPIA     = false;
sysctl.enable_SYSCTL_PERIPH_CLK_I2CA     = false;
sysctl.enable_SYSCTL_PERIPH_CLK_I2CB     = false;
sysctl.enable_SYSCTL_PERIPH_CLK_DACA     = false;
sysctl.enable_SYSCTL_PERIPH_CLK_CLB1     = false;
sysctl.enable_SYSCTL_PERIPH_CLK_CLB2     = false;
sysctl.enable_SYSCTL_PERIPH_CLK_CLB3     = false;
sysctl.enable_SYSCTL_PERIPH_CLK_CLB4     = false;
sysctl.enable_SYSCTL_PERIPH_CLK_FSITXA   = false;
sysctl.enable_SYSCTL_PERIPH_CLK_FSIRXA   = false;
sysctl.enable_SYSCTL_PERIPH_CLK_LINA     = false;
sysctl.enable_SYSCTL_PERIPH_CLK_LINB     = false;
sysctl.enable_SYSCTL_PERIPH_CLK_HICA     = false;
sysctl.enable_SYSCTL_PERIPH_CLK_AESA     = false;
sysctl.enable_SYSCTL_PERIPH_CLK_EPG1     = false;
sysctl.enable_SYSCTL_PERIPH_CLK_DCC0     = false;
sysctl.enable_SYSCTL_PERIPH_CLK_DCC1     = false;
sysctl.splitCode                         = true;
sysctl.enable_SYSCTL_PERIPH_CLK_DACB     = false;

/**
 * Pinmux solution for unlocked pins/peripherals. This ensures that minor changes to the automatic solver in a future
 * version of the tool will not impact the pinmux you originally saw.  These lines can be completely deleted in order to
 * re-solve from scratch.
 */
analog1.analog.$suggestSolution                           = "ANALOG";
analog1.analog["a0/b15/c15/daca_outPin"].$suggestSolution = "A0/B15/C15/DACA_OUT";
analog1.analog["a1/b7/dacb_outPin"].$suggestSolution      = "A1/B7/DACB_OUT";
analog1.analog["a10/b1/c10Pin"].$suggestSolution          = "A10/B1/C10";
analog1.analog["a11/b10/c0Pin"].$suggestSolution          = "A11/B10/C0";
analog1.analog["a12, c1Pin"].$suggestSolution             = "A12, C1";
analog1.analog["a15, c7/b9Pin"].$suggestSolution          = "A15, C7/B9";
analog1.analog["a4/b8, c14Pin"].$suggestSolution          = "A4/B8, C14";
